# CY8C5888LTI_LP097 register map
File version: 0.1
CY8C58LP
Registers are 8-bit, read-write, no defined reset value unless marked. A register's access mark holds for its fields unless they carry their own. Offsets are from the block's base; lines under a group give offsets from that group; [hi:lo] are bit positions; {n}, {i} and the like mark numbered series; 'fields as' and 'values as' point back to an identical list; <NAME> marks a mode.

## Memory map
0x00000000 PWM_{n} (n=1..9)
0x00000000 ADC_SAR — SAR ADC
0x00000000 UART

## PWM_8
Base 0x00000000
0x40006424 PWM_8_COMPARE_Reg 16-bit — UDB.D0 - Assigned Compare Value
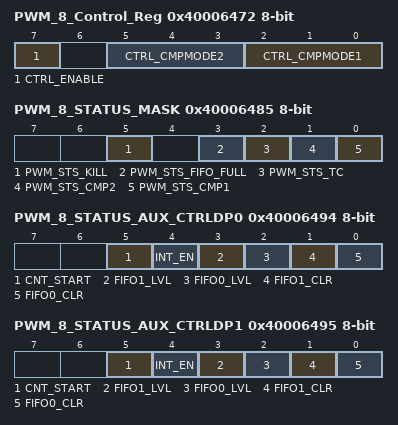
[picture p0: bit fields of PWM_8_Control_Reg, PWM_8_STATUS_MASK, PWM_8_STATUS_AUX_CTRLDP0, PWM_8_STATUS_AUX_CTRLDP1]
0x40006472 PWM_8_Control_Reg — UDB Control Register - Assigned Control Register Value
  [7] CTRL_ENABLE — Enable the PWM
  [5:3] CTRL_CMPMODE2 — Compare mode 2
  [2:0] CTRL_CMPMODE1 — Compare mode 1
0x40006485 PWM_8_STATUS_MASK — UDB Status bits Interrupt Mask Enable Register
  [5] PWM_STS_KILL ro — Enables the Interrupt on Kill
  [3] PWM_STS_FIFO_FULL ro — FIFO Full Status Mask
  [2] PWM_STS_TC ro — Enables the Interrupt on Terminal Count
  [1] PWM_STS_CMP2 ro — Enables the Interrupt on Compare 2
  [0] PWM_STS_CMP1 ro — Enables the Interrupt on Compare 1
0x40006494 PWM_8_STATUS_AUX_CTRLDP0 — UDB Auxilliary Control Register
  [5] CNT_START — FIFO0 clear
    0=E_CNT_START0 (Disable counter); 1=E_CNT_START1 (Enable counter)
  [4] INT_EN
    0=E_INT_EN0 (Interrupt disabled); 1=E_INT_EN1 (Interrupt enabled)
  [3] FIFO1_LVL — FIFO level
    0=E_FIFO_LVL_0 (FIFO LVL: input mode: FIFO not full; output mode: FIFO not empty); 1=E_FIFO_LVL_1 (FIFO LVL: input mode: FIFO at least 1/2 empty; output mode: FIFO at least 1/2 full)
  [2] FIFO0_LVL — FIFO level
    values as FIFO1_LVL
  [1] FIFO1_CLR — FIFO1 clear
    0=E_FIFO_CLR_0 (Normal FIFO operation); 1=E_FIFO_CLR_1 (Clear FIFO state)
  [0] FIFO0_CLR — FIFO0 clear
    values as FIFO1_CLR
0x40006495 PWM_8_STATUS_AUX_CTRLDP1 — UDB Auxilliary Control Register
  fields as PWM_8_STATUS_AUX_CTRLDP0

## PWM_9
Base 0x00000000
0x4000652A PWM_9_COMPARE_Reg 16-bit — UDB.D0 - Assigned Compare Value
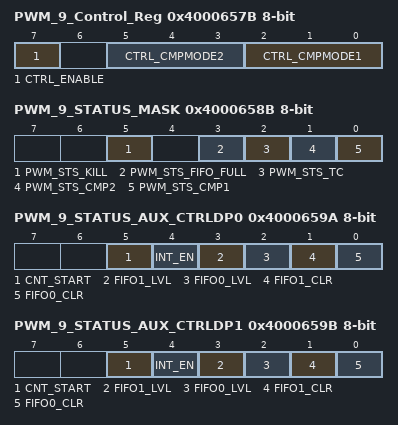
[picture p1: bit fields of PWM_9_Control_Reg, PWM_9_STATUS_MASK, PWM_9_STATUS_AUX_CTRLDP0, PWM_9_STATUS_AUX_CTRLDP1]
0x4000657B PWM_9_Control_Reg — UDB Control Register - Assigned Control Register Value
  [7] CTRL_ENABLE — Enable the PWM
  [5:3] CTRL_CMPMODE2 — Compare mode 2
  [2:0] CTRL_CMPMODE1 — Compare mode 1
0x4000658B PWM_9_STATUS_MASK — UDB Status bits Interrupt Mask Enable Register
  [5] PWM_STS_KILL ro — Enables the Interrupt on Kill
  [3] PWM_STS_FIFO_FULL ro — FIFO Full Status Mask
  [2] PWM_STS_TC ro — Enables the Interrupt on Terminal Count
  [1] PWM_STS_CMP2 ro — Enables the Interrupt on Compare 2
  [0] PWM_STS_CMP1 ro — Enables the Interrupt on Compare 1
0x4000659A PWM_9_STATUS_AUX_CTRLDP0 — UDB Auxilliary Control Register
  [5] CNT_START — FIFO0 clear
    0=E_CNT_START0 (Disable counter); 1=E_CNT_START1 (Enable counter)
  [4] INT_EN
    0=E_INT_EN0 (Interrupt disabled); 1=E_INT_EN1 (Interrupt enabled)
  [3] FIFO1_LVL — FIFO level
    0=E_FIFO_LVL_0 (FIFO LVL: input mode: FIFO not full; output mode: FIFO not empty); 1=E_FIFO_LVL_1 (FIFO LVL: input mode: FIFO at least 1/2 empty; output mode: FIFO at least 1/2 full)
  [2] FIFO0_LVL — FIFO level
    values as FIFO1_LVL
  [1] FIFO1_CLR — FIFO1 clear
    0=E_FIFO_CLR_0 (Normal FIFO operation); 1=E_FIFO_CLR_1 (Clear FIFO state)
  [0] FIFO0_CLR — FIFO0 clear
    values as FIFO1_CLR
0x4000659B PWM_9_STATUS_AUX_CTRLDP1 — UDB Auxilliary Control Register
  fields as PWM_9_STATUS_AUX_CTRLDP0

## PWM_6
Base 0x00000000
0x40006526 PWM_6_COMPARE_Reg 16-bit — UDB.D0 - Assigned Compare Value
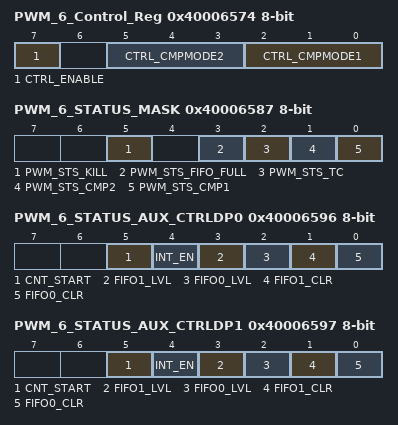
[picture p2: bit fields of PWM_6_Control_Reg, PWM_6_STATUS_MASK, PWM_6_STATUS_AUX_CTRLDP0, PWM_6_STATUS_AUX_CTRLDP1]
0x40006574 PWM_6_Control_Reg — UDB Control Register - Assigned Control Register Value
  [7] CTRL_ENABLE — Enable the PWM
  [5:3] CTRL_CMPMODE2 — Compare mode 2
  [2:0] CTRL_CMPMODE1 — Compare mode 1
0x40006587 PWM_6_STATUS_MASK — UDB Status bits Interrupt Mask Enable Register
  [5] PWM_STS_KILL ro — Enables the Interrupt on Kill
  [3] PWM_STS_FIFO_FULL ro — FIFO Full Status Mask
  [2] PWM_STS_TC ro — Enables the Interrupt on Terminal Count
  [1] PWM_STS_CMP2 ro — Enables the Interrupt on Compare 2
  [0] PWM_STS_CMP1 ro — Enables the Interrupt on Compare 1
0x40006596 PWM_6_STATUS_AUX_CTRLDP0 — UDB Auxilliary Control Register
  [5] CNT_START — FIFO0 clear
    0=E_CNT_START0 (Disable counter); 1=E_CNT_START1 (Enable counter)
  [4] INT_EN
    0=E_INT_EN0 (Interrupt disabled); 1=E_INT_EN1 (Interrupt enabled)
  [3] FIFO1_LVL — FIFO level
    0=E_FIFO_LVL_0 (FIFO LVL: input mode: FIFO not full; output mode: FIFO not empty); 1=E_FIFO_LVL_1 (FIFO LVL: input mode: FIFO at least 1/2 empty; output mode: FIFO at least 1/2 full)
  [2] FIFO0_LVL — FIFO level
    values as FIFO1_LVL
  [1] FIFO1_CLR — FIFO1 clear
    0=E_FIFO_CLR_0 (Normal FIFO operation); 1=E_FIFO_CLR_1 (Clear FIFO state)
  [0] FIFO0_CLR — FIFO0 clear
    values as FIFO1_CLR
0x40006597 PWM_6_STATUS_AUX_CTRLDP1 — UDB Auxilliary Control Register
  fields as PWM_6_STATUS_AUX_CTRLDP0
